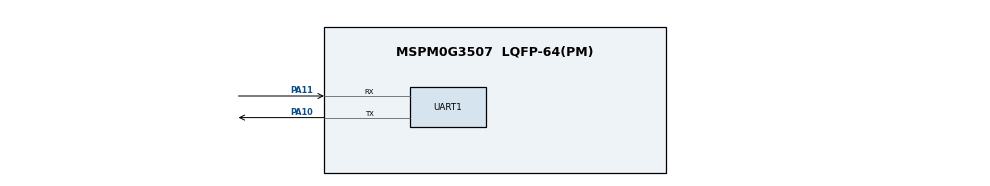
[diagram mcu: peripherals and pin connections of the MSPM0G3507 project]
//@cliArgs --device "MSPM0G350X" --package "LQFP-64(PM)" --part "Default"
//@v2CliArgs --device "MSPM0G3507" --package "LQFP-64(PM)"
// @cliArgs --board /ti/boards/LP_MSPM0G3507 --rtos nortos

/**
 * Import the modules used in this configuration.
 */
const SYSCTL = scripting.addModule("/ti/driverlib/SYSCTL");
const UART = scripting.addModule("/ti/driverlib/UART", {}, false);
const UART1 = UART.addInstance();

/**
 * Write custom configuration values to the imported modules.
 */

const Board = scripting.addModule("/ti/driverlib/Board", {}, false);

SYSCTL.forceDefaultClkConfig = true;

UART1.$name = "UART_0";
UART1.profile = "CONFIG_PROFILE_1";
UART1.peripheral.$assign = "UART0";
UART1.targetBaudRate = 115200;
UART1.enableInternalLoopback = false;
UART1.enabledInterrupts = ["RX"];
UART1.enableFIFO = false;
UART1.peripheral.rxPin.$assign = "PA11";
UART1.peripheral.txPin.$assign = "PA10";
